AUTOSAR XML (schema 00053)
standard types defined: boolean
package /Services
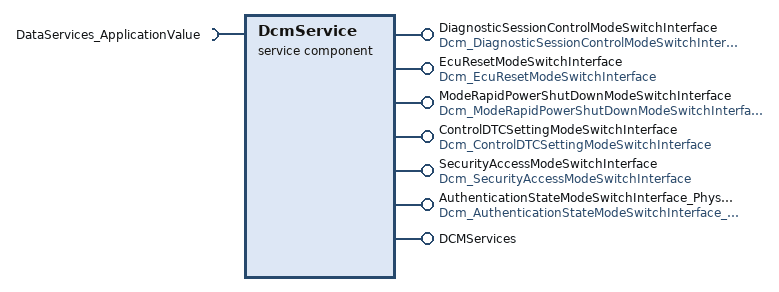
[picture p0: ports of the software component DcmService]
  service sw component type DcmService
    require port DataServices_ApplicationValue: client-com-spec=ReadData, required-interface=DataServices_ApplicationValue
    7 x provide port:
      DiagnosticSessionControlModeSwitchInterface: mode-switch-sender-com-spec{enhanced-mode-api=false, mode-group=diagnosticSession}, provided-interface=Dcm_DiagnosticSessionControlModeSwitchInterface
      EcuResetModeSwitchInterface: mode-switch-sender-com-spec{enhanced-mode-api=false, mode-group=ecuReset}, provided-interface=Dcm_EcuResetModeSwitchInterface
      ModeRapidPowerShutDownModeSwitchInterface: mode-switch-sender-com-spec{enhanced-mode-api=false, mode-group=modeRapidPowerShutDown}, provided-interface=Dcm_ModeRapidPowerShutDownModeSwitchInterface
      ControlDTCSettingModeSwitchInterface: mode-switch-sender-com-spec{enhanced-mode-api=false, mode-group=controlDTCSetting}, provided-interface=Dcm_ControlDTCSettingModeSwitchInterface
      SecurityAccessModeSwitchInterface: mode-switch-sender-com-spec{enhanced-mode-api=false, mode-group=securityAccess}, provided-interface=Dcm_SecurityAccessModeSwitchInterface
      AuthenticationStateModeSwitchInterface_Physical: mode-switch-sender-com-spec{enhanced-mode-api=false, mode-group=authenticationState}, provided-interface=Dcm_AuthenticationStateModeSwitchInterface_Physical
      DCMServices: provided-interface=DCMServices
        provided-com-specs:
          operation=GetSecurityLevel, queue-length=1
          operation=GetSesCtrlType, queue-length=1
          operation=ResetToDefaultSession, queue-length=1
          operation=SetActiveDiagnostic, queue-length=1
    behavior Behavior: data-type-mapping=DcmModeTypes
      4 x operation invoked event:
        InvokeGetSecurityLevel: start-on-event=GetSecurityLevel, operation=DCMServices.GetSecurityLevel
        InvokeGetSesCtrlType: start-on-event=GetSesCtrlType, operation=DCMServices.GetSesCtrlType
        InvokeResetToDefaultSession: start-on-event=ResetToDefaultSession, operation=DCMServices.ResetToDefaultSession
        InvokeSetActiveDiagnostic: start-on-event=SetActiveDiagnostic, operation=DCMServices.SetActiveDiagnostic
      5 x runnable:
        DcmReadData: symbol=DcmService_ReadData
          sync call ReadApplicationValue: operation=DataServices_ApplicationValue.ReadData
        GetSecurityLevel: can-be-invoked-concurrently=true, symbol=Dcm_GetSecurityLevel
        GetSesCtrlType: can-be-invoked-concurrently=true, symbol=Dcm_GetSesCtrlType
        ResetToDefaultSession: can-be-invoked-concurrently=true, symbol=Dcm_ResetToDefaultSession
        SetActiveDiagnostic: can-be-invoked-concurrently=true, symbol=Dcm_SetActiveDiagnostic
  mode switch interface Dcm_DiagnosticSessionControlModeSwitchInterface: is-service=true
    mode group diagnosticSession: type=DcmDiagnosticSessionControl
  data type mapping set DcmModeTypes
    mode-request-type-maps:
      implementation-data-type=Rte_ModeType_DcmDiagnosticSessionControl, mode-group=DcmDiagnosticSessionControl
      implementation-data-type=Rte_ModeType_DcmEcuReset, mode-group=DcmEcuReset
      implementation-data-type=Rte_ModeType_DcmModeRapidPowerShutDown, mode-group=DcmModeRapidPowerShutDown
      implementation-data-type=Rte_ModeType_DcmControlDTCSetting, mode-group=DcmControlDTCSetting
      implementation-data-type=Rte_ModeType_DcmSecurityAccess, mode-group=DcmSecurityAccess
      implementation-data-type=Rte_ModeType_DcmAuthenticationState_Physical, mode-group=DcmAuthenticationState_Physical
  5 x mode switch interface, all with is-service=true:
    Dcm_EcuResetModeSwitchInterface
      mode group ecuReset: type=DcmEcuReset
    Dcm_ModeRapidPowerShutDownModeSwitchInterface
      mode group modeRapidPowerShutDown: type=DcmModeRapidPowerShutDown
    Dcm_ControlDTCSettingModeSwitchInterface
      mode group controlDTCSetting: type=DcmControlDTCSetting
    Dcm_SecurityAccessModeSwitchInterface
      mode group securityAccess: type=DcmSecurityAccess
    Dcm_AuthenticationStateModeSwitchInterface_Physical
      mode group authenticationState: type=DcmAuthenticationState_Physical
  client server interface DCMServices: is-service=true, service-kind=DIAGNOSTIC-COMMUNICATION-MANAGER
    4 x operation:
      GetSecurityLevel: possible-error=[DCMServices/E_OK, DCMServices/E_NOT_OK]
        arg SecLevel: type=Dcm_SecLevelType, direction=OUT
      GetSesCtrlType: possible-error=[DCMServices/E_OK, DCMServices/E_NOT_OK]
        arg SesCtrlType: type=Dcm_SesCtrlType, direction=OUT
      ResetToDefaultSession: possible-error=[DCMServices/E_OK, DCMServices/E_NOT_OK]
      SetActiveDiagnostic: possible-error=DCMServices/E_OK
        arg active: type=boolean, direction=IN
    error E_OK: error-code=0
    error E_NOT_OK: error-code=1
  impl type Dcm_SecLevelType: category=VALUE, base-type=Native7, type-emitter=Rte_Dcm_Type.h
  impl type Dcm_SesCtrlType: category=VALUE, base-type=Native7, type-emitter=Rte_Dcm_Type.h
  base type BooleanBase: category=FIXED_LENGTH, base-type-size=8, base-type-encoding=BOOLEAN, native-declaration=boolean
  swc implementation DcmServicesImplementation: programming-language=C, behavior=DcmService/Behavior
  swc bsw mapping DcmServicesMapping: bsw-behavior=Behavior, swc-behavior=DcmService/Behavior
    runnable-mappings:
      bsw-entity=Dcm_GetSecurityLevel_Entity, swc-runnable=GetSecurityLevel
      bsw-entity=Dcm_GetSesCtrlType_Entity, swc-runnable=GetSesCtrlType
      bsw-entity=Dcm_ResetToDefaultSession_Entity, swc-runnable=ResetToDefaultSession
      bsw-entity=Dcm_SetActiveDiagnostic_Entity, swc-runnable=SetActiveDiagnostic
  base type DcmNativeGetSecurityLevel: category=FIXED_LENGTH, base-type-size=8, base-type-encoding=NONE, native-declaration=Dcm_SecLevelType *
  base type DcmNativeGetSesCtrlType: category=FIXED_LENGTH, base-type-size=8, base-type-encoding=NONE, native-declaration=Dcm_SesCtrlType *
  base type DcmNativeSetActiveDiagnostic: category=FIXED_LENGTH, base-type-size=8, base-type-encoding=NONE, native-declaration=boolean
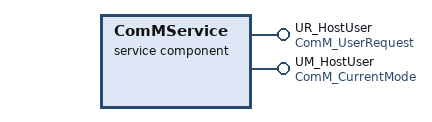
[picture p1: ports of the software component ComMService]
  service sw component type ComMService
    provide port UR_HostUser: provided-interface=ComM_UserRequest
      provided-com-specs:
        operation=GetCurrentComMode, queue-length=1
        operation=GetCurrentPNCComMode, queue-length=1
        operation=GetMaxComMode, queue-length=1
        operation=GetRequestedComMode, queue-length=1
        operation=RequestComMode, queue-length=1
    provide port UM_HostUser: mode-switch-sender-com-spec{enhanced-mode-api=false, mode-group=currentMode}, provided-interface=ComM_CurrentMode
    behavior Behavior: port-api-option{port-defined-argument-value{value=0, value-type=ComM_UserHandleType}, port=UR_HostUser}
      5 x operation invoked event:
        InvokeGetCurrentComMode: start-on-event=GetCurrentComMode, operation=UR_HostUser.GetCurrentComMode
        InvokeGetCurrentPNCComMode: start-on-event=GetCurrentPNCComMode, operation=UR_HostUser.GetCurrentPNCComMode
        InvokeGetMaxComMode: start-on-event=GetMaxComMode, operation=UR_HostUser.GetMaxComMode
        InvokeGetRequestedComMode: start-on-event=GetRequestedComMode, operation=UR_HostUser.GetRequestedComMode
        InvokeRequestComMode: start-on-event=RequestComMode, operation=UR_HostUser.RequestComMode
      5 x runnable, all with can-be-invoked-concurrently=true:
        GetCurrentComMode: symbol=ComM_GetCurrentComMode
        GetCurrentPNCComMode: symbol=ComM_GetCurrentPNCComMode
        GetMaxComMode: symbol=ComM_GetMaxComMode
        GetRequestedComMode: symbol=ComM_GetRequestedComMode
        RequestComMode: symbol=ComM_RequestComMode
  client server interface ComM_UserRequest: is-service=true
    5 x operation:
      GetCurrentComMode: possible-error=[ComM_UserRequest/E_OK, ComM_UserRequest/E_NOT_OK]
        arg ComMode: type=ComM_ModeType, direction=OUT
      GetCurrentPNCComMode: possible-error=[ComM_UserRequest/E_OK, ComM_UserRequest/E_NOT_OK, COMM_E_MULTIPLE_PNC_ASSIGNED, COMM_E_NO_PNC_ASSIGNED]
        arg ComMode: type=ComM_ModeType, direction=OUT
      GetMaxComMode: possible-error=[ComM_UserRequest/E_OK, ComM_UserRequest/E_NOT_OK]
        arg ComMode: type=ComM_ModeType, direction=OUT
      GetRequestedComMode: possible-error=[ComM_UserRequest/E_OK, ComM_UserRequest/E_NOT_OK]
        arg ComMode: type=ComM_ModeType, direction=OUT
      RequestComMode: possible-error=[ComM_UserRequest/E_OK, ComM_UserRequest/E_NOT_OK, COMM_E_MODE_LIMITATION]
        arg ComMode: type=ComM_ModeType, direction=IN
    5 x error:
      E_OK: error-code=0
      E_NOT_OK: error-code=1
      COMM_E_MODE_LIMITATION: error-code=2
      COMM_E_MULTIPLE_PNC_ASSIGNED: error-code=3
      COMM_E_NO_PNC_ASSIGNED: error-code=4
  mode switch interface ComM_CurrentMode: is-service=true
    mode group currentMode: type=ComMMode
  mode declaration group ComMMode: category=ALPHABETIC_ORDER, initial-mode=COMM_NO_COMMUNICATION
    mode COMM_FULL_COMMUNICATION
    mode COMM_NO_COMMUNICATION
    mode COMM_SILENT_COMMUNICATION
  impl type ComM_ModeType: category=VALUE, base-type=ComM_ModeTypeBase, type-emitter=Rte_ComM_Type.h
  base type ComM_ModeTypeBase: category=FIXED_LENGTH, base-type-size=8, base-type-encoding=NONE, native-declaration=uint8
  impl type ComM_UserHandleType: category=VALUE, base-type=ComM_UserHandleTypeBase, type-emitter=Rte_ComM_Type.h
  base type ComM_UserHandleTypeBase: category=FIXED_LENGTH, base-type-size=16, base-type-encoding=NONE, native-declaration=uint16
  swc implementation ComMImplementation: programming-language=C, behavior=ComMService/Behavior
  swc bsw mapping ComMMapping: bsw-behavior=Behavior, swc-behavior=ComMService/Behavior, synchronized-mode-groups=swc-bsw-synchronized-mode-group-prototype={bsw-mode-group=UM_HostUser, swc-mode-group=UM_HostUser.currentMode}
    runnable-mappings:
      bsw-entity=ComM_GetCurrentComMode_Entity, swc-runnable=GetCurrentComMode
      bsw-entity=ComM_GetCurrentPNCComMode_Entity, swc-runnable=GetCurrentPNCComMode
      bsw-entity=ComM_GetMaxComMode_Entity, swc-runnable=GetMaxComMode
      bsw-entity=ComM_GetRequestedComMode_Entity, swc-runnable=GetRequestedComMode
      bsw-entity=ComM_RequestComMode_Entity, swc-runnable=RequestComMode
